# psoc4100tp register map
Vendor: Infineon Technologies; Series: PSOC4100Tp; File version: 1.0
CPU: CM0PLUS r0p1, little endian, no MPU, no FPU, VTOR, 2 interrupt priority bits, 23 interrupts
Registers are 32-bit, read-write, reset 0x0 unless marked. A register's access mark holds for its fields unless they carry their own. Offsets are from the block's base; [hi:lo] are bit positions.

## WCO — 32KHz Oscillator
Base 0x40220000
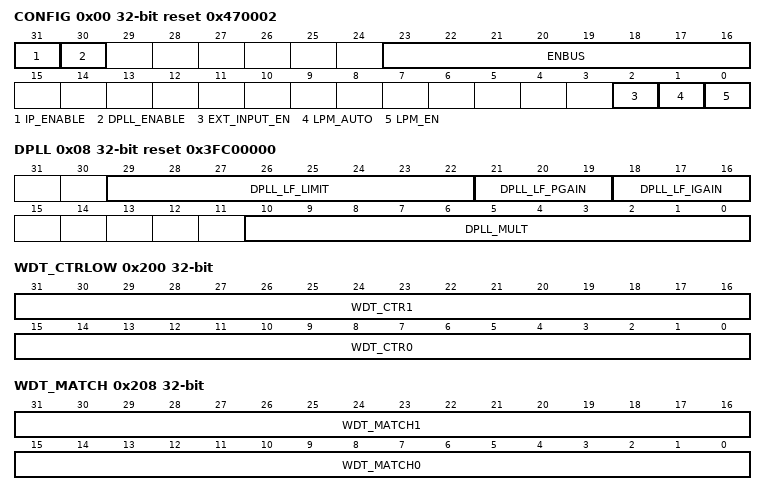
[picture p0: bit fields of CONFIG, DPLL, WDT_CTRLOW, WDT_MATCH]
0x00 CONFIG reset 0x470002 — WCO Configuration Register
  [31] IP_ENABLE
  [30] DPLL_ENABLE
  [23:16] ENBUS
  [2] EXT_INPUT_EN — Disables the load resistor and allows external clock input for XTAL pin
  [1] LPM_AUTO
  [0] LPM_EN
0x04 STATUS ro — WCO Status Register
  [0] OUT_BLNK_A — Indicates that output has transitioned - This bit is intended for Test Mode Only and is not a reliable indicator.
0x08 DPLL reset 0x3FC00000 — WCO DPLL Register
  [29:22] DPLL_LF_LIMIT — Maximum IMO offset allowed (used to prevent DPLL dynamics from selecting an IMO frequency that the logic cannot support)
  [21:19] DPLL_LF_PGAIN — DPLL Loop Filter Proportionial Gain Setting 0x0 - 0.0625 0x1 - 0.125 0x2 - 0.25 0x3 - 0.5 0x4 - 1.0 0x5 - 2.0 0x6 - 4.0 0x7 - 8.0
  [18:16] DPLL_LF_IGAIN — DPLL Loop Filter Integral Gain Setting 0x0 - 0.0625 0x1 - 0.125 0x2 - 0.25 0x3 - 0.5 0x4 - 1.0 0x5 - 2.0 0x6 - 4.0 0x7 - 8.0
  [10:0] DPLL_MULT — Multiplier to determine IMO frequency in multiples of the WCO frequency Fimo = (DPLL_MULT + 1) * Fwco
0x200 WDT_CTRLOW ro — Watchdog Counters 0/1
  [31:16] WDT_CTR1 — Current value of WDT Counter 1
  [15:0] WDT_CTR0 — Current value of WDT Counter 0
0x204 WDT_CTRHIGH ro — Watchdog Counter 2
  [31:0] WDT_CTR2 — Current value of WDT Counter 2
0x208 WDT_MATCH — Watchdog counter match values
  [31:16] WDT_MATCH1 — Match value for Watchdog Counter 1
  [15:0] WDT_MATCH0 — Match value for Watchdog Counter 0
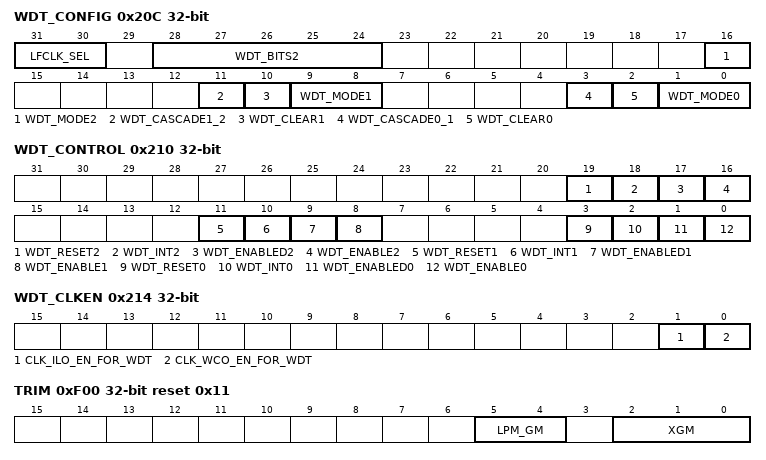
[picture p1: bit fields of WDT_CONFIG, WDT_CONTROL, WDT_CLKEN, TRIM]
0x20C WDT_CONFIG — Watchdog Counters Configuration
  [31:30] LFCLK_SEL
  [28:24] WDT_BITS2 — Bit to observe for WDT_INT2: 0: Assert when bit0 of WDT_CTR2 toggles (one int every tick) .. 31: Assert when bit31 of WDT_CTR2 toggles (one int every 2^31 ticks)
  [16] WDT_MODE2 — Watchdog Counter 2 Mode.
    0=NOTHING (Free running counter with no interrupt requests); 1=INT (Free running counter with interrupt request when a specified bit in CTR2 toggles (see WDT_BITS2))
  [11] WDT_CASCADE1_2 — Cascade Watchdog Counters 1,2. Counter 2 increments the cycle after WDT_CTR1=WDT_MATCH1. It is allowed to cascade all three WDT counters. 0: Independent counters 1: Cascaded counters. When cascading all three counters, WDT_CLEAR1 must be 1
  [10] WDT_CLEAR1 — Clear Watchdog Counter when WDT_CTR1=WDT_MATCH1. In other words WDT_CTR1 divides LFCLK by (WDT_MATCH1+1). 0: Free running counter 1: Clear on match
  [9:8] WDT_MODE1 — Watchdog Counter Action on Match (WDT_CTR1=WDT_MATCH1).
    0=NOTHING (Do nothing); 1=INT (Assert WDT_INTx); 2=RESET (Assert WDT Reset - Not Supported - here for backwards compatibility); 3=INT_THEN_RESET (Assert WDT_INTx, assert WDT Reset after 3rd unhandled interrupt - Not supported - here for backwards compatibility.)
  [3] WDT_CASCADE0_1 — Cascade Watchdog Counters 0,1. Counter 1 increments the cycle after WDT_CTR0=WDT_MATCH0. 0: Independent counters 1: Cascaded counters
  [2] WDT_CLEAR0 — Clear Watchdog Counter when WDT_CTR0=WDT_MATCH0. In other words WDT_CTR0 divides LFCLK by (WDT_MATCH0+1). 0: Free running counter 1: Clear on match
  [1:0] WDT_MODE0 — Watchdog Counter Action on Match (WDT_CTR0=WDT_MATCH0).
    0=NOTHING (Do nothing); 1=INT (Assert WDT_INTx); 2=RESET (Assert WDT Reset - Not Supported - here for backwards compatibility); 3=INT_THEN_RESET (Assert WDT_INTx, assert WDT Reset after 3rd unhandled interrupt. Not supported - here for Backwards compatibility.)
0x210 WDT_CONTROL — Watchdog Counters Control
  [19] WDT_RESET2 write-1-sets
  [18] WDT_INT2 write-1-clears — WDT Interrupt Request. This bit is set by hardware as configured by this registers. This bit must be cleared by firmware. After WDT_CTR2, WDT_CONTROL must be read for the hardware to internally remove the clear flag. Failure to do this may result in missing the next interrupt.
  [17] WDT_ENABLED2 ro
  [16] WDT_ENABLE2
  [11] WDT_RESET1 write-1-sets
  [10] WDT_INT1 write-1-clears — WDT Interrupt Request. This bit is set by hardware as configured by this registers. This bit must be cleared by firmware. After WDT_CTR1, WDT_CONTROL must be read for the hardware to internally remove the clear flag. Failure to do this may result in missing the next interrupt.
  [9] WDT_ENABLED1 ro
  [8] WDT_ENABLE1
  [3] WDT_RESET0 write-1-sets
  [2] WDT_INT0 write-1-clears
  [1] WDT_ENABLED0 ro
  [0] WDT_ENABLE0
0x214 WDT_CLKEN — Watchdog Counters Clock Enable
  [1] CLK_ILO_EN_FOR_WDT — Enables the ILO clock for use by the WDT logic. Wait at least 4 ILO clock cycles for a change to take effect. Must be 0 when switching WDT_CONFIG.LFCLK_SEL. Should be 0 if CLK_WCO_EN_FOR_WDT=1.
  [0] CLK_WCO_EN_FOR_WDT — Enables the WCO clock for use by the WDT logic. Wait at least 4 WCO clock cycles for a change to take effect. Must be 0 when switching WDT_CONFIG.LFCLK_SEL. Should be 0 if CLK_ILO_EN_FOR_WDT=1
0xF00 TRIM reset 0x11 — WCO Trim Register
  [5:4] LPM_GM — GM setting for LPM (bandwidth = DC/ms) - Used when WCO.LPM_AUTO=0 or when LPM_AUTO=1 and not in DeepSleep mode.
  [2:0] XGM — Amplifier GM setting - Used when WCO.LPM_AUTO=0 or when LPM_AUTO=1 and not in DeepSleep mode. 0x0 - 3370 nA 0x1 - 2620 nA 0x2 - 2250 nA 0x3 - 1500 nA 0x4 - 1870 nA 0x5 - 1120 nA 0x6 - 750 nA 0x7 - 0 nA

## SPCIF — Flash Control Interface
Base 0x40110000
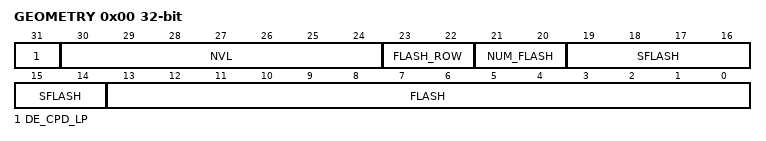
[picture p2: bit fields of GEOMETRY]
0x00 GEOMETRY (reset mask 0x80000000) — Flash/NVL geometry information
  [31] DE_CPD_LP — 0': SRAM busy wait loop has not been copied. '1': Busy wait loop has been written into SRAM.
  [30:24] NVL ro — NVLatch size in Byte multiples (chip dependent): '0': 0 Bytes '1': 1 Byte ... '127': 127 Bytes
  [23:22] FLASH_ROW ro — Page size in 64 Byte multiples (chip dependent): '0': 64 byte '1': 128 byte '2': 192 byte '3': 256 byte The page size is used to determine the number of Bytes in a page for Flash page based operations (e.g. PGM_PAGE). Note: the field name FLASH_ROW is misleading, as this field specifies the number of Bytes in a page, rather than the number of Bytes in a row. In a single plane flash macro architecture, a page consists of a single row. However, in a multi plane flash macro architecture, a page consists of multiple rows from different planes.
  [21:20] NUM_FLASH ro — Number of flash macros (chip dependent): '0': 1 flash macro '1': 2 flash macros '2': 3 flash macros '3': 4 flash macros
  [19:14] SFLASH ro — Supervisory flash capacity in 256 Byte multiples (chip dependent). If multiple flash macros are present, this field provides the supervisory flash capacity of all flash macros together: '0': 256 Bytes. '1': 2*256 Bytes. ... '63': 64*256 Bytes.
  [13:0] FLASH ro — Regular flash capacity in 256 Byte multiples (chip dependent). If multiple flash macros are present, this field provides the flash capacity of all flash macros together: '0': 256 Bytes. '1': 2*256 Bytes. ... '16383': 16384*256 Bytes.
0x1C NVL_WR_DATA — NVL write data register
  [7:0] DATA — Data to be written to NVLatch array
0x7F0 INTR — SPCIF interrupt request register
  [0] TIMER write-1-clears — Timer counter value reaches '0'. Set to '1', when event is detected. Write INTR field with '1', to clear bit. Write INTR_SET field with '1', to set bit.
0x7F4 INTR_SET — SPCIF interrupt set request register
  [0] TIMER write-1-sets — Write INTR_SET field with '1' to set corresponding INTR field.
0x7F8 INTR_MASK — SPCIF interrupt mask register
  [0] TIMER — Mask for corresponding field in INTR register.
0x7FC INTR_MASKED ro — SPCIF interrupt masked request register
  [0] TIMER — Logical and of corresponding request and mask fields.
